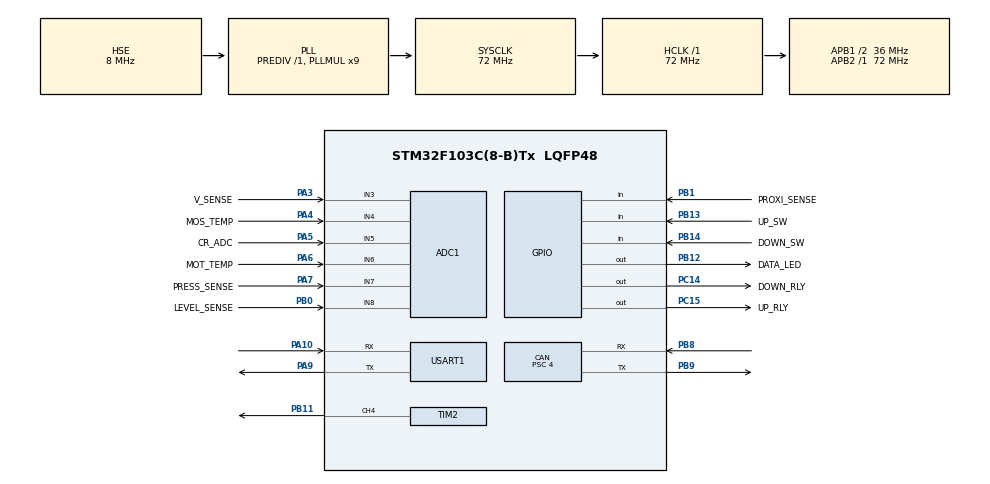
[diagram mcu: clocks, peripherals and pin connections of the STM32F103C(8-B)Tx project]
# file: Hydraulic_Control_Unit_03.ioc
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ADC1.Channel-2\#ChannelRegularConversion=ADC_CHANNEL_3
ADC1.Channel-3\#ChannelRegularConversion=ADC_CHANNEL_4
ADC1.Channel-4\#ChannelRegularConversion=ADC_CHANNEL_5
ADC1.Channel-5\#ChannelRegularConversion=ADC_CHANNEL_6
ADC1.Channel-6\#ChannelRegularConversion=ADC_CHANNEL_7
ADC1.Channel-7\#ChannelRegularConversion=ADC_CHANNEL_8
ADC1.ContinuousConvMode=ENABLE
ADC1.DataAlign=ADC_DATAALIGN_RIGHT
ADC1.EnableRegularConversion=ENABLE
ADC1.NbrOfConversion=6
ADC1.NbrOfConversionFlag=1
ADC1.Rank-2\#ChannelRegularConversion=1
ADC1.Rank-3\#ChannelRegularConversion=2
ADC1.Rank-4\#ChannelRegularConversion=3
ADC1.Rank-5\#ChannelRegularConversion=4
ADC1.Rank-6\#ChannelRegularConversion=5
ADC1.Rank-7\#ChannelRegularConversion=6
ADC1.SamplingTime-2\#ChannelRegularConversion=ADC_SAMPLETIME_71CYCLES_5
ADC1.SamplingTime-3\#ChannelRegularConversion=ADC_SAMPLETIME_71CYCLES_5
ADC1.SamplingTime-4\#ChannelRegularConversion=ADC_SAMPLETIME_71CYCLES_5
ADC1.SamplingTime-5\#ChannelRegularConversion=ADC_SAMPLETIME_71CYCLES_5
ADC1.SamplingTime-6\#ChannelRegularConversion=ADC_SAMPLETIME_71CYCLES_5
ADC1.SamplingTime-7\#ChannelRegularConversion=ADC_SAMPLETIME_71CYCLES_5
ADC1.master=1
CAN.BS1=CAN_BS1_13TQ
CAN.BS2=CAN_BS2_4TQ
CAN.CalculateBaudRate=500000
CAN.CalculateTimeBit=2000
CAN.CalculateTimeQuantum=111.11111111111111
CAN.Prescaler=4
Dma.ADC1.0.Direction=DMA_PERIPH_TO_MEMORY
Dma.ADC1.0.Instance=DMA1_Channel1
Dma.ADC1.0.MemDataAlignment=DMA_MDATAALIGN_HALFWORD
Dma.ADC1.0.MemInc=DMA_MINC_ENABLE
Dma.ADC1.0.Mode=DMA_CIRCULAR
Dma.ADC1.0.PeriphDataAlignment=DMA_PDATAALIGN_HALFWORD
Dma.ADC1.0.PeriphInc=DMA_PINC_DISABLE
Dma.ADC1.0.Priority=DMA_PRIORITY_HIGH
Dma.Request0=ADC1
Mcu.Family=STM32F1
Mcu.Name=STM32F103C(8-B)Tx
Mcu.Package=LQFP48
NVIC.ADC1_2_IRQn=true\:0\:0\:false\:false\:true\:true\:true\:true
NVIC.DMA1_Channel1_IRQn=true\:0\:0\:false\:false\:true\:false\:true\:true
NVIC.PriorityGroup=NVIC_PRIORITYGROUP_4
NVIC.USB_LP_CAN1_RX0_IRQn=true\:0\:0\:false\:false\:true\:true\:true\:true
PA10.Mode=Asynchronous
PA10.Signal=USART1_RX
PA13.GPIO_Label=SWDIO
PA13.Mode=Serial_Wire
PA13.Signal=SYS_JTMS-SWDIO
PA14.GPIO_Label=SWCLK
PA14.Mode=Serial_Wire
PA14.Signal=SYS_JTCK-SWCLK
PA3.GPIO_Label=V_SENSE
PA3.Signal=ADCx_IN3
PA4.GPIO_Label=MOS_TEMP
PA4.Signal=ADCx_IN4
PA5.GPIO_Label=CR_ADC
PA5.Signal=ADCx_IN5
PA6.GPIO_Label=MOT_TEMP
PA6.Signal=ADCx_IN6
PA7.GPIO_Label=PRESS_SENSE
PA7.Signal=ADCx_IN7
PA9.Mode=Asynchronous
PA9.Signal=USART1_TX
PB0.GPIO_Label=LEVEL_SENSE
PB0.Signal=ADCx_IN8
PB1.GPIO_Label=PROXI_SENSE
PB1.GPIO_PuPd=GPIO_PULLUP
PB1.Signal=GPIO_Input
PB11.Signal=S_TIM2_CH4
PB12.GPIO_Label=DATA_LED
PB12.Signal=GPIO_Output
PB13.GPIO_Label=UP_SW
PB13.GPIO_PuPd=GPIO_PULLUP
PB13.Signal=GPIO_Input
PB14.GPIO_Label=DOWN_SW
PB14.GPIO_PuPd=GPIO_PULLUP
PB14.Signal=GPIO_Input
PB8.Mode=CAN_Activate
PB8.Signal=CAN_RX
PB9.Mode=CAN_Activate
PB9.Signal=CAN_TX
PC14-OSC32_IN.GPIO_Label=DOWN_RLY
PC14-OSC32_IN.Signal=GPIO_Output
PC15-OSC32_OUT.GPIO_Label=UP_RLY
PC15-OSC32_OUT.Signal=GPIO_Output
PD0-OSC_IN.Mode=HSE-External-Oscillator
PD0-OSC_IN.Signal=RCC_OSC_IN
PD1-OSC_OUT.Mode=HSE-External-Oscillator
PD1-OSC_OUT.Signal=RCC_OSC_OUT
ProjectManager.HeapSize=0x200
ProjectManager.StackSize=0x400
ProjectManager.TargetToolchain=STM32CubeIDE
RCC.ADCPresc=RCC_ADCPCLK2_DIV6
RCC.AHBFreq_Value=72000000
RCC.APB1CLKDivider=RCC_HCLK_DIV2
RCC.APB1Freq_Value=36000000
RCC.APB1TimFreq_Value=72000000
RCC.APB2Freq_Value=72000000
RCC.APB2TimFreq_Value=72000000
RCC.HCLKFreq_Value=72000000
RCC.PLLMUL=RCC_PLL_MUL9
RCC.PLLSourceVirtual=RCC_PLLSOURCE_HSE
RCC.SYSCLKFreq_VALUE=72000000
RCC.SYSCLKSource=RCC_SYSCLKSOURCE_PLLCLK
RCC.USBFreq_Value=72000000
SH.ADCx_IN3.0=ADC1_IN3,IN3
SH.ADCx_IN4.0=ADC1_IN4,IN4
SH.ADCx_IN5.0=ADC1_IN5,IN5
SH.ADCx_IN6.0=ADC1_IN6,IN6
SH.ADCx_IN7.0=ADC1_IN7,IN7
SH.ADCx_IN8.0=ADC1_IN8,IN8
SH.S_TIM2_CH4.0=TIM2_CH4,PWM Generation4 CH4
TIM2.Channel-PWM\ Generation4\ CH4=TIM_CHANNEL_4
USART1.VirtualMode=VM_ASYNC
board=custom

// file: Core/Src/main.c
/* USER CODE BEGIN Header */
/**
  ******************************************************************************
  * @file           : main.c
  * @brief          : Main program body
  ******************************************************************************
  * @attention
  *
  * Copyright (c) 2026 STMicroelectronics.
  * All rights reserved.
  *
  * This software is licensed under terms that can be found in the LICENSE file
  * in the root directory of this software component.
  * If no LICENSE file comes with this software, it is provided AS-IS.
  *
  ******************************************************************************
  */
/* USER CODE END Header */
#include "main.h"
#include "adc.h"
#include "can.h"
#include "dma.h"
#include "tim.h"
#include "usart.h"
#include "gpio.h"

/* USER CODE BEGIN Includes */

#include "app.h"
#include "can_if.h"

/* USER CODE END Includes */

/* USER CODE BEGIN PV */

  uint16_t adc_raw[6];

/* USER CODE END PV */

void SystemClock_Config(void);

/* USER CODE BEGIN 0 */

void HAL_CAN_RxFifo0MsgPendingCallback(CAN_HandleTypeDef *hcan)
{
    CAN_RxHeaderTypeDef hdr;
    uint8_t data[8];

    HAL_CAN_GetRxMessage(hcan, CAN_RX_FIFO0, &hdr, data);

    can_if_process_rx(&hdr, data);
}

/* USER CODE END 0 */

int main(void)
{

  /* MCU Configuration--------------------------------------------------------*/

  /* Reset of all peripherals, Initializes the Flash interface and the Systick. */
  HAL_Init();

  /* Configure the system clock */
  SystemClock_Config();

  /* Initialize all configured peripherals */
  MX_GPIO_Init();
  MX_DMA_Init();
  MX_ADC1_Init();
  MX_TIM2_Init();
  MX_CAN_Init();
  MX_USART1_UART_Init();
  /* USER CODE BEGIN 2 */
  /* ---- Start Peripherals ---- */

  HAL_ADC_Start_DMA(&hadc1, (uint32_t*)adc_raw, 6);

  HAL_TIM_PWM_Start(&htim2, TIM_CHANNEL_4);

  HAL_CAN_Start(&hcan);

/* ---- Application Init ---- */

  app_init();

  /* USER CODE END 2 */

  /* Infinite loop */
  /* USER CODE BEGIN WHILE */
  while (1)
  {
	 app_run();
    /* USER CODE END WHILE */

  }
}

void SystemClock_Config(void)
{
  RCC_OscInitTypeDef RCC_OscInitStruct = {0};
  RCC_ClkInitTypeDef RCC_ClkInitStruct = {0};
  RCC_PeriphCLKInitTypeDef PeriphClkInit = {0};

  /** Initializes the RCC Oscillators according to the specified parameters
  * in the RCC_OscInitTypeDef structure.
  */
  RCC_OscInitStruct.OscillatorType = RCC_OSCILLATORTYPE_HSE;
  RCC_OscInitStruct.HSEState = RCC_HSE_ON;
  RCC_OscInitStruct.HSEPredivValue = RCC_HSE_PREDIV_DIV1;
  RCC_OscInitStruct.HSIState = RCC_HSI_ON;
  RCC_OscInitStruct.PLL.PLLState = RCC_PLL_ON;
  RCC_OscInitStruct.PLL.PLLSource = RCC_PLLSOURCE_HSE;
  RCC_OscInitStruct.PLL.PLLMUL = RCC_PLL_MUL9;
  if (HAL_RCC_OscConfig(&RCC_OscInitStruct) != HAL_OK)
  {
    Error_Handler();
  }

  /** Initializes the CPU, AHB and APB buses clocks
  */
  RCC_ClkInitStruct.ClockType = RCC_CLOCKTYPE_HCLK|RCC_CLOCKTYPE_SYSCLK
                              |RCC_CLOCKTYPE_PCLK1|RCC_CLOCKTYPE_PCLK2;
  RCC_ClkInitStruct.SYSCLKSource = RCC_SYSCLKSOURCE_PLLCLK;
  RCC_ClkInitStruct.AHBCLKDivider = RCC_SYSCLK_DIV1;
  RCC_ClkInitStruct.APB1CLKDivider = RCC_HCLK_DIV2;
  RCC_ClkInitStruct.APB2CLKDivider = RCC_HCLK_DIV1;

  if (HAL_RCC_ClockConfig(&RCC_ClkInitStruct, FLASH_LATENCY_2) != HAL_OK)
  {
    Error_Handler();
  }
  PeriphClkInit.PeriphClockSelection = RCC_PERIPHCLK_ADC;
  PeriphClkInit.AdcClockSelection = RCC_ADCPCLK2_DIV6;
  if (HAL_RCCEx_PeriphCLKConfig(&PeriphClkInit) != HAL_OK)
  {
    Error_Handler();
  }
}

void Error_Handler(void)
{
  __disable_irq();
  while (1)
  {
  }
}
